# DISPC register map
Vendor: Texas Instruments
Registers are 32-bit, access per field, reset 0x0 unless marked. A register's access mark holds for its fields unless they carry their own. Offsets are as the file gives them; [hi:lo] are bit positions; {n}, {i} and the like mark numbered series; 'fields as' and 'values as' point back to an identical list.

## DISPC (part 2 of 6)
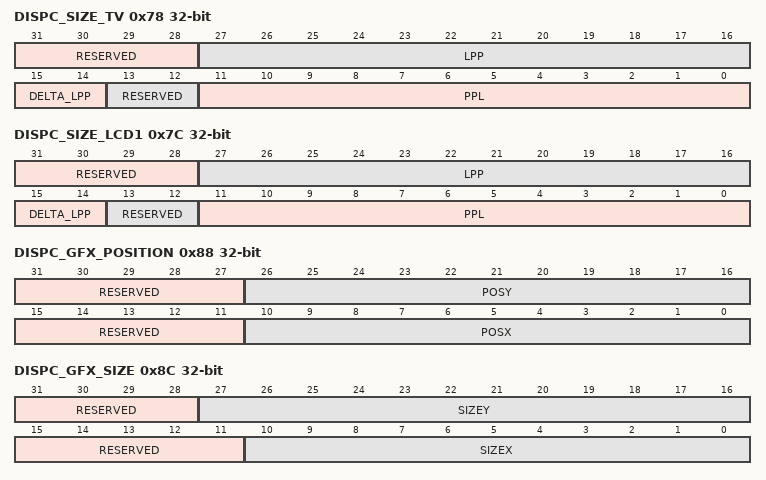
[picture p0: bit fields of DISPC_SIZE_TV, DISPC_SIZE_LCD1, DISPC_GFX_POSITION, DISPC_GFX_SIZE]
0x78 DISPC_SIZE_TV — The register configures the size of the TV output field (interlace), frame (progressive) (horizontal and vertical). Shadow register, updated on EVSYNC. A delta value is used to indicate if the odd field has same vertical size as the even field or +/- one line.
  [31:28] RESERVED ro — Write 0s for future compatibility. Reads return 0.
  [27:16] LPP rw — Lines per panel encoded value (from 1 to 4096) to specify the number of lines per panel.
  [15:14] DELTA_LPP rw — Indicates the delta size value of the odd field compared to the even field
    0=Same size; 1=PlusOne (Odd size = Even size +1); 2=MinusOne (Odd size = Even Size –1)
  [13:12] RESERVED ro — Write 0s for future compatibility. Reads return 0.
  [11:0] PPL rw — Pixels per line encoded value (from 1 to 4096) to specify the number of pixels contains within each line on the display.
0x7C DISPC_SIZE_LCD1 — The register configures the panel size (horizontal and vertical). Shadow register, updated on VFP start period of primary LCD. A delta value is used to indicate if the odd field has same vertical size as the even field or +/- one line.
  [31:28] RESERVED ro — Write 0s for future compatibility. Reads return 0.
  [27:16] LPP rw — Lines per panel encoded value (from 1 to 4096) to specify the number of lines per panel (program to value minus 1).
  [15:14] DELTA_LPP rw — Indicates the delta size value of the odd field compared to the even field
    0=Same size; 1=PlusOne (Odd size = Even size +1); 2=MinusOne (Odd size = Even Size -1)
  [13:12] RESERVED ro — Write 0s for future compatibility. Reads return 0.
  [11:0] PPL rw — Pixels per line encoded value (from 1 to 4096) to specify the number of pixels contains within each line on the display (program to value minus 1). In STALL mode, any value is valid. In non STALL mode, only values multiple of 8 pixels are valid.
0x80 DISPC_GFX_BA_j_0 rw — The register configures the base address of the graphics buffer displayed in the graphics window (0 and 1 :for ping-pong mechanism with external trigger, based on the field polarity, 0 only used when graphics pipeline on the LCD output and 0 and 1 when on the TV output). Shadow register, updated on VFP start period of primary LCD or VFP start period of the secondary LCD or VFP start period of the third LCD or EVSYNC or when.GOWB is set to 1 by software and current WB frame is finished (no more data in the write-back pipeline). The synchronization event is defined based on the output using the pipeline: primary LCD, secondary LCD, third LCD, TV output or write-back to the memory
  [31:0] BA — Graphics base address Base address of the graphics buffer (aligned on pixel size boundary) (in case 1-, 2-, and 4-bpp, byte alignment is required, in case of RGB24 packed format, 4-pixel alignment is required) When the TILER is addressed, the bits: [28:27] = 0x0 for 8-bit tiled [28:27] = 0x1 for 16-bit tiled [28:27] = 0x2 for 32-bit tiled [28:27] = 0x3 for page mode [31:29] = 0x0 for 0-degree view [31:29] = 0x1 for 180-degree view + mirroring [31:29] = 0x2 for 0-degree view + mirroring [31:29] = 0x3 for 180-degree view [31:29] = 0x4 for 270-degree view + mirroring [31:29] = 0x5 for 270-degree view [31:29] = 0x6 for 90-degree view [31:29] = 0x7 for 90-degree view + mirroring Otherwise the bits indicated the corresponding bit address to access the SDRAM.
0x84 DISPC_GFX_BA_j_1 rw — The register configures the base address of the graphics buffer displayed in the graphics window (0 and 1 :for ping-pong mechanism with external trigger, based on the field polarity, 0 only used when graphics pipeline on the LCD output and 0 and 1 when on the TV output). Shadow register, updated on VFP start period of primary LCD or VFP start period of the secondary LCD or VFP start period of the third LCD or EVSYNC or when.GOWB is set to 1 by software and current WB frame is finished (no more data in the write-back pipeline). The synchronization event is defined based on the output using the pipeline: primary LCD, secondary LCD, third LCD, TV output or write-back to the memory
  fields as DISPC_GFX_BA_j_0
0x88 DISPC_GFX_POSITION — The register configures the position of the graphics window. Shadow register, updated on VFP start period of primary LCD or VFP start period of the secondary LCD or VFP start period of the third LCD or EVSYNC or when.GOWB is set to 1 by software and current WB frame is finished (no more data in the write-back pipeline). The synchronization event is defined based on the output using the pipeline: primary LCD, secondary LCD, third LCD, TV output or write-back to the memory
  [31:27] RESERVED ro — Write 0s for future compatibility. Reads return 0.
  [26:16] POSY rw — Y position of the graphics window. Encoded value (from 0 to 2047) to specify the Y position of the graphics window on the screen. The line at the top has the Y-position 0.
  [15:11] RESERVED ro — Write 0s for future compatibility. Reads return 0.
  [10:0] POSX rw — X position of the graphics window. Encoded value (from 0 to 2047) to specify the X position of the graphics window on the screen. The first pixel on the left of the screen has the X-position 0.
0x8C DISPC_GFX_SIZE — The register configures the size of the graphics window. Shadow register, updated on VFP start period of primary LCD or VFP start period of the secondary LCD or VFP start period of the third LCD or EVSYNC or when.GOWB is set to 1 by software and current WB frame is finished (no more data in the write-back pipeline). The synchronization event is defined based on the output using the pipeline: primary LCD, secondary LCD, third LCD, TV output or write-back to the memory
  [31:28] RESERVED ro — Write 0s for future compatibility. Reads return 0.
  [27:16] SIZEY rw — Number of lines of the graphics window. Encoded value (from 1 to 4096) to specify the number of lines of the graphics window (program to value minus 1).
  [15:11] RESERVED ro — Write 0s for future compatibility. Reads return 0.
  [10:0] SIZEX rw — Number of pixels of the graphics window. Encoded value (from 1 to 2048) to specify the number of pixels per line of the graphics window (program to value minus 1).
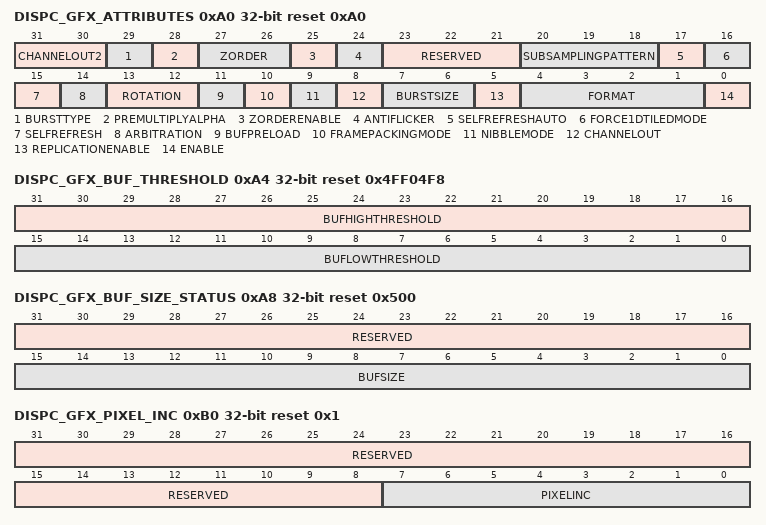
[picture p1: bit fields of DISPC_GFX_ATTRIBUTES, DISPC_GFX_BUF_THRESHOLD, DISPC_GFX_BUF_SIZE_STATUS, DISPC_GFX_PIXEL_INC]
0xA0 DISPC_GFX_ATTRIBUTES reset 0xA0 — The register configures the graphics attributes. Shadow register, updated on VFP start period of primary LCD or VFP start period of the secondary LCD or VFP start period of the third LCD or EVSYNC or when.GOWB is set to 1 by software and current WB frame is finished (no more data in the write-back pipeline). The synchronization event is defined based on the output using the pipeline: primary LCD, secondary LCD, third LCD, TV output or write-back to the memory
  [31:30] CHANNELOUT2 rw — It is not used if CHANNELOUT is set to TV. Reserved when CHANNELOUT = 1 (should set to zero) wr: immediate
    0=Primary_LCD_output_selected; 1=Secondary_LCD_output_selected; 2=Third_LCD_output_selected; 3=Write-back output to the memory selected
  [29] BURSTTYPE rw — The type of burst can be INCR (incremental) or BLCK (2D block). The 2D block is required when the TILER is targeted by the DMA engine. (It does not apply to the palette loading OCP requests using INCR burst only)
    0=INC (INC burst type is used.); 1=2D_block_burst_type_is_used
  [28] PREMULTIPLYALPHA rw — The field configures the DISPC GFX to process incoming data as premultiplied alpha data or non premultiplied alpha data. Default setting is non premultiplied alpha data.
    0=PremultipliedAlpha (Non premultiplyalpha data color component); 1=PremultipliedAlpha (Premultiplyalpha data color component)
  [27:26] ZORDER rw — Z-Order defining the priority of the layer compared to others when overlaying. It is software responsibility to ensure that each layer connected to the same overlay manager has a different z-order value. If bit 25 is set to 0, the ZORDER bit field is ignored and replaced by the value 0.
    0=Z-order 0: layer above solid background color and below layer with higher Z-order values; 1=Z-order 1: layer above layer with z-order value of 0 and below layers with z-order values of 2 and 3; 3=Z-order 3: layer above all the other layers; 2=Z-order 2: layer above layers with z-order value of 0 and 1 and below layer with z-order value of 3
  [25] ZORDERENABLE rw — Z-order Enable. The bit field ZORDER is only used when the Z-order is enabled.
    0=Z-order disabled. The Z-order of the layer is 0.; 1=ZorderEnb (Z-order enabled. The Z-order is defined by the bit field ZORDER (bits 26 and 27).)
  [24] ANTIFLICKER rw — Antiflicker filtering using a 3-tap filter with hardcoded coefficients (1/4, 1/2, 1/4)
    0=AFDis (Antiflicker disabled.); 1=AFEnb (Antiflicker enabled.)
  [23:21] RESERVED ro — Write 0s for future compatibility. Reads return 0.
  [20:18] SUBSAMPLINGPATTERN rw — Subsampling pattern setting.
  [17] SELFREFRESHAUTO rw — Automatic self-refresh mode
    0=SelfRefreshAutoDis (The transition from Selfrefresh disabled to enabled is controlled by software); 1=SelfRefreshAutoEn (The transition from Selfrefresh disabled to enabled is controlled only by hardware)
  [16] FORCE1DTILEDMODE rw — Force TILED regions access to 1D or 2D.
    0=TiledRegions2DAccess (2D accesses for tiled regions); 1=TiledRegions1DAccess (1D accesses for tiled regions)
  [15] SELFREFRESH rw — Enables the self refresh of the graphics window from its own DMA buffer. This bit should be set only after having set the GO bit of the channel and read back a zero in its field.
    0=SelfRefreshDis (The graphics pipeline accesses the interconnect to fetch data from the system memory.); 1=SelfRefreshEnb (The graphics pipeline does not need anymore to fetch data from memory. Only the graphics DMA buffer is used. It takes effect after the frame has been loaded in the DMA buffer.)
  [14] ARBITRATION rw — Determines the priority of the graphics pipeline. When the graphics pipeline is one of the high priority pipelines. The arbitration wheel gives always the priority first to the high priority pipelines using round-robin between them. When there is only normal priority pipelines sending requests, the round-robin applies between them.
    0=NormalPrio (The graphics pipeline is one of the normal priority pipeline.); 1=HighPrio (The graphics pipeline is one of the high priority pipeline.)
  [13:12] ROTATION rw — Graphics rotation flag
    0=No rotation; 1=Rot90 (Rotation by 90 degrees); 3=Rot270 (Rotation by 270 degrees); 2=Rot180 (Rotation by 180 degrees)
  [11] BUFPRELOAD rw — Graphics preload value
    0=DefVal (Hardware prefetches pixels up to the preload value defined in the preload register); 1=HighThres (Hardware prefetches pixels up to high threshold value)
  [10] FRAMEPACKINGMODE rw — Frame packing mode control.
    0=FPMDis (Frame Packing mode is disabled); 1=FPMEnb (Frame Packing mode is enabled)
  [9] NIBBLEMODE rw — Graphics nibble mode (only for 1-, 2- and 4 bpp)NOTE: BITMAP formats and associated Nibble Mode are not supported in this family of devices. .
    0=NibMDis (Nibble mode is disabled); 1=NibMEnb (Nibble mode is enabled)
  [8] CHANNELOUT rw — Graphics Channel Out configuration: LCD, WB or TV. wr: immediate
    0=LCDOpSel (LCD output or WB to the memory selected. bit fields 31 and 30 defines the output associated (primary, secondary or write-back).); 1=TVOpSel (TV output selected)
  [7:6] BURSTSIZE rw — Graphics DMA burst size
    0=Burst2x128 (2 × 128-bit bursts); 1=Burst4x128 (4 × 128-bit bursts); 2=Burst8x128 (8 × 128-bit bursts)
  [5] REPLICATIONENABLE rw — Graphics replication enabled: RGB . ARGB, and RGBA formats are converted into ARGB32-8888 using replication of the MSBs or 0s
    0=GRLogEnb (Disable graphics replication logic. The conversion to ARGB32-8888 is done by adding 0s for the LSBs); 1=GRLogDis (Enable graphics replication logic. The conversion to ARGB32-8888 is done by duplicating the MSBs for the LSBs)
  [4:1] FORMAT rw — Graphics format. It defines the pixel format when fetching the graphics picture into memory.
    6=RGB16 (RGB16-565); 10=RGBx12-4444; 7=ARGB16_1 (ARGB16-1555); 13=RGBA32 (RGBA32-8888); 8=xRGB24-8888 (32-bit container); 9=RGB24p (RGB24-888 (24-bit container)); 11=RGBA12 (RGBA12-4444); 4=xRGB12-4444; 5=ARGB16 (ARGB16-4444); 15=xRGB15-1555; 12=ARGB32 (ARGB32-8888); 3=BGRA32 (BGRA32-8888); 14=BitMap8 (RGBx24-8888 (24-bit RGB aligned on MSB of the 32-bit container))
  [0] ENABLE rw — Graphics enable
    0=Graphics disabled (graphics pipeline inactive and graphics window not present); 1=GraphicsEnb (Graphics enabled (graphics pipeline active and graphics window present on the screen))
0xA4 DISPC_GFX_BUF_THRESHOLD rw reset 0x4FF04F8 — The register configures the graphics buffer. Shadow register, updated on VFP start period of primary LCD or VFP start period of the secondary LCD or VFP start period of the third LCD or EVSYNC or when.GOWB is set to 1 by software and current WB frame is finished (no more data in the write-back pipeline). The synchronization event is defined based on the output using the pipeline: primary LCD, secondary LCD, third LCD, TV output or write-back to the memory
  [31:16] BUFHIGHTHRESHOLD — DMA buffer high threshold number of 128 bits defining the threshold value
  [15:0] BUFLOWTHRESHOLD — DMA buffer low threshold number of 128 bits defining the threshold value. The value put in this register must always be greater than zero.
0xA8 DISPC_GFX_BUF_SIZE_STATUS ro reset 0x500 — The register defines the Graphics buffer size
  [31:16] RESERVED — Write 0s for future compatibility. Reads return 0.
  [15:0] BUFSIZE — DMA buffer size in number of 128 bits
0xAC DISPC_GFX_ROW_INC rw reset 0x1 — The register configures the number of bytes to increment at the end of the row. Shadow register, updated on VFP start period of primary LCD or VFP start period of the secondary LCD or VFP start period of the third LCD or EVSYNC or when.GOWB is set to 1 by software and current WB frame is finished (no more data in the write-back pipeline). The synchronization event is defined based on the output using the pipeline: primary LCD, secondary LCD, third LCD, TV output or write-back to the memory
  [31:0] ROWINC — Number of bytes to increment at the end of the row Encoded unsigned value to specify the number of bytes to increment at the end of the row in the graphics buffer. The value 0 is invalid. The value 1 means next pixel. The value 1+n*bpp means increment of n pixels. The value 1- (n+1)*bpp means decrement of n pixels.
0xB0 DISPC_GFX_PIXEL_INC reset 0x1 — The register configures the number of bytes to increment between two pixels. For more information, see, Predecimation. Shadow register, updated on VFP start period of primary LCD or VFP start period of the secondary LCD or VFP start period of the third LCD or EVSYNC or when .GOWB is set to 1 by software and current WB frame is finished (no more data in the write-back pipeline). The synchronization event is defined based on the output using the pipeline: primary LCD, secondary LCD, third LCD, TV output or write-back to the memory
  [31:8] RESERVED ro — Write 0s for future compatibility. Reads return 0.
  [7:0] PIXELINC rw — Number of bytes to increment between two pixels. Encoded unsigned value (from 1 to 255) to specify the number of bytes between two pixels in the graphics buffer. The value 0 is invalid. The value 1 means next pixel. The value 1+n*bpp means increment of n pixels.
0xB8 DISPC_GFX_TABLE_BA rw — The register configures the base address of the palette buffer or the gamma table buffer. Shadow register, updated on VFP start period of primary LCD or VFP start period of the secondary LCD or VFP start period of the third LCD or EVSYNC or when.GOWB is set to 1 by software and current WB frame is finished (no more data in the write-back pipeline). The synchronization event is defined based on the output using the pipeline: primary LCD, secondary LCD, third LCD, TV output or write-back to the memory. NOTE: CLUT and BITMAP formats, and associated palette buffer, are not supported in this family of devices.
  [31:0] TABLEBA — Base address of the palette/gamma table buffer (24-bit entries in 32-bit containers, aligned on 32-bit boundary).NOTE: CLUT and BITMAP formats, and associated palette buffer, are not supported in this family of devices. .
0xBC DISPC_VID1_BA_j_0 rw — The register configures the base address of the video buffer for the video window 1 (DISPC_VID1_BA_0 and DISPC_VID1_BA_1 for ping-pong mechanism with external trigger, based on the field polarity otherwise only DISPC_VID1_BA_0 is used). Shadow register, updated on VFP start period of primary LCD or VFP start period of the secondary LCD or or VFP start period of the third LCD or EVSYNC or when.GOWB is set to 1 by software and current WB frame is finished (no more data in the write-back pipeline). The synchronization event is defined based on the output using the pipeline: primary LCD, secondary LCD, third LCD, TV output or write-back to the memory
  [31:0] BA — Video base address Base address of the video buffer (aligned on pixel size boundary except in case of RGB24 packed format, 4-pixel alignment is required; in case of YUV4:2:2, 2-pixel alignment is required, and YUV4:2:0, byte alignment is supported)). It case of YUV4:2:0 format, it indicates the base address of the Y buffer. When the TILER is addressed, the bits: [28:27] = 0x0 for 8-bit tiled [28:27] = 0x1 for 16-bit tiled [28:27] = 0x2 for 32-bit tiled [28:27] = 0x3 for page mode [31:29] = 0x0 for 0-degree view [31:29] = 0x1 for 180-degree view + mirroring [31:29] = 0x2 for 0-degree view + mirroring [31:29] = 0x3 for 180-degree view [31:29] = 0x4 for 270-degree view + mirroring [31:29] = 0x5 for 270-degree view [31:29] = 0x6 for 90-degree view [31:29] = 0x7 for 90-degree view + mirroring Otherwise the bits indicated the corresponding bit address to access the SDRAM.
0xC0 DISPC_VID1_BA_j_1 rw — The register configures the base address of the video buffer for the video window 1 (DISPC_VID1_BA_0 and DISPC_VID1_BA_1 for ping-pong mechanism with external trigger, based on the field polarity otherwise only DISPC_VID1_BA_0 is used). Shadow register, updated on VFP start period of primary LCD or VFP start period of the secondary LCD or or VFP start period of the third LCD or EVSYNC or when.GOWB is set to 1 by software and current WB frame is finished (no more data in the write-back pipeline). The synchronization event is defined based on the output using the pipeline: primary LCD, secondary LCD, third LCD, TV output or write-back to the memory
  fields as DISPC_VID1_BA_j_0
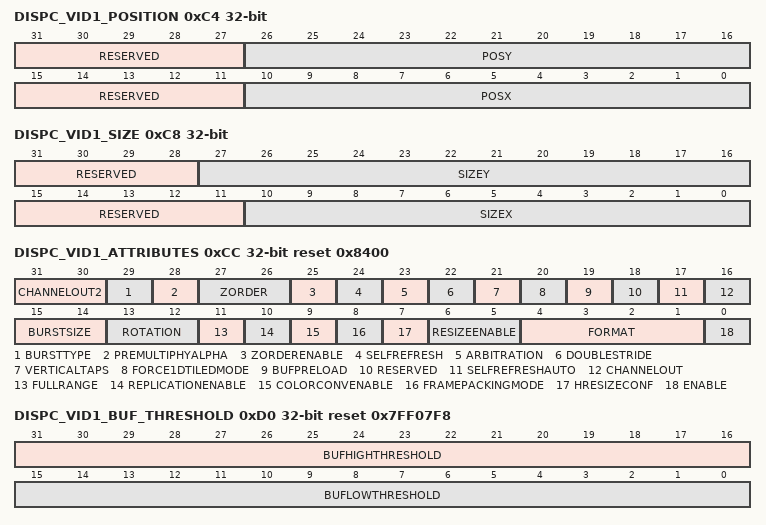
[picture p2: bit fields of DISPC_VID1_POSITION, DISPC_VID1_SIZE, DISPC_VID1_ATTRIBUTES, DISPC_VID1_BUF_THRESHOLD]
0xC4 DISPC_VID1_POSITION — The register configures the position of the video window 1. Shadow register, updated on VFP start period of primary LCD or VFP start period of the secondary LCD or VFP start period of the third LCD or EVSYNC or when.GOWB is set to 1 by software and current WB frame is finished (no more data in the write-back pipeline). The synchronization event is defined based on the output using the pipeline: primary LCD, secondary LCD, third LCD, TV output or write-back to the memory
  [31:27] RESERVED ro — Write 0s for future compatibility. Reads return 0.
  [26:16] POSY rw — Y position of the video window 1 Encoded value (from 0 to 2047) to specify the Y position of the video window 1 .The line at the top has the Y-position 0.
  [15:11] RESERVED ro — Write 0s for future compatibility. Reads return 0.
  [10:0] POSX rw — X position of the video window 1 Encoded value (from 0 to 2047) to specify the X position of the video window 1. The first pixel on the left of the display screen has the X-position 0.
0xC8 DISPC_VID1_SIZE — The register configures the size of the video window 1. Shadow register, updated on VFP start period of primary LCD or VFP start period of the secondary LCD or VFP start period of the third LCD, orEVSYNC or when.GOWB is set to 1 by software and current WB frame is finished (no more data in the write-back pipeline). The synchronization event is defined based on the output using the pipeline: primary LCD, secondary LCD, third LCD, TV output or write-back to the memory
  [31:28] RESERVED ro — Write 0s for future compatibility. Reads return 0.
  [27:16] SIZEY rw — Number of lines of the video 1 Encoded value (from 1 to 4096) to specify the number of lines of the video window 1. Program to value minus 1.
  [15:11] RESERVED ro — Write 0s for future compatibility. Reads return 0.
  [10:0] SIZEX rw — Number of pixels of the video window 1 Encoded value (from 1 to 2048) to specify the number of pixels of the video window 1. Program to value minus 1.
0xCC DISPC_VID1_ATTRIBUTES reset 0x8400 — The register configures the attributes of the video window 1. Shadow register, updated on VFP start period of primary LCD or VFP start period of the secondary LCD or VFP start period of the third LCD or EVSYNC or when.GOWB is set to 1 by software and current WB frame is finished (no more data in the write-back pipeline). The synchronization event is defined based on the output using the pipeline: primary LCD, secondary LCD, third LCD, TV output or write-back to the memory
  [31:30] CHANNELOUT2 rw — It is not used if CHANNELOUT is set to TV. Reserved when CHANNELOUT = 1 (should be set to zero) wr: immediate
    0=PrimaryLCDSel (Primary LCD output selected.); 1=SecondaryLCDSel (Secondary LCD output selected.); 2=ThirdLCDSel (Third LCD output selected.); 3=WriteBacksel (Write-back output to the memory selected.)
  [29] BURSTTYPE rw — The type of burst can be INCR (incremental) or BLCK (2D block). The 2D block is required when the TILER is targeted by the DMA engine.
    0=INC (INC burst type is used.); 1=BLCK (2D block burst type is used.)
  [28] PREMULTIPHYALPHA rw — The field configures the DISPC VID1 to process incoming data as premultiplied alpha data or non premultiplied alpha data. Default setting is non premultiplied alpha data.
    values as DISPC_GFX_ATTRIBUTES.PREMULTIPLYALPHA
  [27:26] ZORDER rw — Z-Order defining the priority of the layer compared to others when overlaying. It is software responsibility to ensure that each layer connected to the same overlay manager has a different z-order value. If bit 25 is set to 0, the ZORDER bit field is ignored and replaced by the value 0.
    values as DISPC_GFX_ATTRIBUTES.ZORDER
  [25] ZORDERENABLE rw — Z-order Enable. The bit field ZORDER is only used when the Z-order is enabled.
    values as DISPC_GFX_ATTRIBUTES.ZORDERENABLE
  [24] SELFREFRESH rw — Enables the self refresh of the video window from its own DMA buffer only.
    0=SelfRefreshDis (The video pipeline accesses the interconnect to fetch data from the system memory.); 1=SelfRefreshEnb (The video pipeline does not need anymore to fetch data from memory. Only the DMA buffer associated with the video1 is used. It takes effect after the frame has been loaded in the DMA buffer.)
  [23] ARBITRATION rw — Determines the priority of the video pipeline. The video pipeline is one of the high priority pipeline. The arbitration gives always the priority first to the high priority pipelines using round-robin between them. When there is only normal priority pipelines sending requests, the round-robin applies between them.
    0=NormalPrio (The video pipeline is one of the normal priority pipeline.); 1=HighPrio (The video pipeline is one of the high priority pipeline.)
  [22] DOUBLESTRIDE rw — Determines if the stride for CbCr buffer is the 1x or 2x of the Y buffer stride. It is only used in case of YUV4:2:0.
    0=Initial (The CbCr stride value is equal to the Y stride.); 1=Double (The CbCr stride value is double to the Y stride.)
  [21] VERTICALTAPS rw — Video vertical resize tap number. The vertical polyphase filter can be configured in 3-tap or 5-tap configuration. According to the number of taps, the maximum input picture width is double while using 3-tap compared to 5-tap.
    0=taps3 (3 taps are used for the vertical filtering logic. The 2 other taps are not used. The associated bit fields for the 2 other taps coefficients do not need to be initialized.); 1=taps5 (5 taps are used for the vertical filtering logic.)
  [20] FORCE1DTILEDMODE rw — Force TILED regions access to 1D or 2D.
    values as DISPC_GFX_ATTRIBUTES.FORCE1DTILEDMODE
  [19] BUFPRELOAD rw — Video Preload Value
    values as DISPC_GFX_ATTRIBUTES.BUFPRELOAD
  [18] RESERVED ro — Write 0s for future compatibility. Reads return 0.
  [17] SELFREFRESHAUTO rw — Automatic self-refresh mode
    0=SelfRefreshAutoDis (The transition from SELFREFRESH disabled to enabled is controlled by SW.); 1=SelfRefreshAutoEn (The transition from SELFREFRESH disabled to enabled is controlled only by hardware.)
  [16] CHANNELOUT rw — Video channel out configuration: LCD, WB or TV. wr: immediate
    0=LCDOp (LCD output or WB to the memory selected. bit fields 31 and 30 defines the output associated (primary, secondary or write-back).); 1=TVOp (TV output selected)
  [15:14] BURSTSIZE rw — Video DMA burst size
    0=Burst2x128b (2x128bit bursts); 1=Burst4x128b (4x128bit bursts); 2=Burst8x128b (8x128bit bursts)
  [13:12] ROTATION rw — Video rotation flag
    values as DISPC_GFX_ATTRIBUTES.ROTATION
  [11] FULLRANGE rw — Color space conversion full range setting.
    0=Limrange (Limited range selected: 16 subtracted from Y before color space conversion); 1=Full range selected: Y is not modified before the color space conversion
  [10] REPLICATIONENABLE rw
    0=VRepLDis (Disable Video replication logic); 1=VRepLEnb (Enable Video replication logic)
  [9] COLORCONVENABLE rw — Enable the color space conversion. The hardware does not enable/disable the conversion based on the pixel format. The bit field shall be reset when the format is not YUV.
    0=ColSpCDis (Disable Color Space Conversion YUV to RGB); 1=ColSpCEnb (Enable Color Space Conversion YUV to RGB)
  [8] FRAMEPACKINGMODE rw — Frame packing mode control.
    values as DISPC_GFX_ATTRIBUTES.FRAMEPACKINGMODE
  [7] HRESIZECONF ro — Write 0s for future compatibility. Reads return 0.
  [6:5] RESIZEENABLE rw — Video Resize Enable
    0=ReSizeProc (Disable both horizontal and vertical resize processing); 1=HReSize (Enable the horizontal resize processing); 3=HVReSize (Enable both horizontal and vertical resize processing); 2=VReSize (Enable the vertical resize processing)
  [4:1] FORMAT rw — Video Format. It defines the pixel format when fetching the video 1 picture into memory.
    6=RGB16 (RGB16-565); 1=RGBx12 (RGB12x-4444); 10=YUV2 (YUV2 4:2:2 co-sited); 7=ARGB16_1 (ARGB16-1555); 13=RGBA32 (RGBA32-8888); 0=NV12 (NV12 4:2:0 2 buffers (Y + UV)); 2=RGBA12 (RGBA12-4444); 8=xRGB24-8888 (32-bit container); 9=RGB24p (RGB24-888 (24-bit container)); 11=UYVY (UYVY 4:2:2 co-sited); 5=ARGB16 (ARGB16-4444); 15=xRGB15-1555; 12=ARGB32 (ARGB32-8888); 4=xRGB12-4444; 3=BGRA32 (BGRA32-8888); 14=xRGB12 (RGBx24-8888 (24-bit RGB aligned on MSB of the 32-bit container))
  [0] ENABLE rw — Video Enable
    0=Video disabled (video pipeline inactive and window not present); 1=VideoEnb (Video enabled (video pipeline active and window present on the screen))
0xD0 DISPC_VID1_BUF_THRESHOLD rw reset 0x7FF07F8 — The register configures the video buffer associated with the video pipeline 1. Shadow register, updated on VFP start period of primary LCD or VFP start period of the secondary LCD or VFP start period of the third LCD or EVSYNC or when.GOWB is set to 1 by software and current WB frame is finished (no more data in the write-back pipeline). The synchronization event is defined based on the output using the pipeline: primary LCD, secondary LCD, third LCD, TV output or write-back to the memory
  [31:16] BUFHIGHTHRESHOLD — Video DMA buffer high threshold number of 128 bits defining the threshold value
  [15:0] BUFLOWTHRESHOLD — DMA buffer low threshold number of 128 bits defining the threshold value
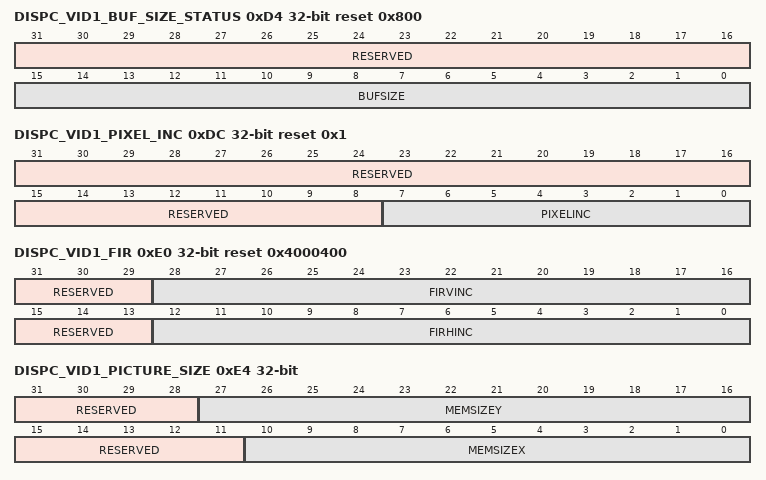
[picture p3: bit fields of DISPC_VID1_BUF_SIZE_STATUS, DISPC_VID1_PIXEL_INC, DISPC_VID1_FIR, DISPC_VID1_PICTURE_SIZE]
0xD4 DISPC_VID1_BUF_SIZE_STATUS ro reset 0x800 — The register defines the Video buffer size for the video pipeline 1.
  [31:16] RESERVED — Write 0s for future compatibility. Reads return 0.
  [15:0] BUFSIZE — Video 1 DMA buffer size in number of 128-bits
0xD8 DISPC_VID1_ROW_INC rw reset 0x1 — The register configures the number of bytes to increment at the end of the row for the buffer associated with the video window 1. Shadow register, updated on VFP start period of primary LCD or VFP start period of the secondary LCD or VFP start period of the third LCD or EVSYNC or when.GOWB is set to 1 by software and current WB frame is finished (no more data in the write-back pipeline). The synchronization event is defined based on the output using the pipeline: primary LCD, secondary LCD, third LCD, TV output or write-back to the memory
  [31:0] ROWINC — Number of bytes to increment at the end of the row Encoded signed value (from 21 to 2) to specify the number of bytes to increment at the end of the row in the video buffer. The value 0 is invalid. The value 1 means next pixel. The value 1 + n * bpp means increment of n pixels. The value 1 (n + 1)* bpp means decrement of n pixels.
0xDC DISPC_VID1_PIXEL_INC reset 0x1 — The register configures the number of bytes to increment between two pixels for the buffer associated with the video window 2. For more information, see, Predecimation.The register is used only when the TILER is not present in the system in order to perform low performance rotation. When the TILER IP is present it is highly recommended to use it for performing the rotation. Shadow register, updated on VFP start period of primary LCD or VFP start period of the secondary LCD or VFP start period of the third LCD orEVSYNC or when .GOWB is set to 1 by software and current WB frame is finished (no more data in the write-back pipeline). The synchronization event is defined based on the output using the pipeline: primary LCD, secondary LCD, third LCD, TV output or write-back to the memory
  [31:8] RESERVED ro — Write 0s for future compatibility. Reads return 0.
  [7:0] PIXELINC rw — Number of bytes to increment between two pixels. Encoded unsigned value (from 1 to 255) to specify the number of bytes between two pixels in the video buffer. The value 0 is invalid. The value 1 means next pixel. The value 1 + n * bpp means increment of n pixels. For YUV4:2:0, maximum supported value is 128.
0xE0 DISPC_VID1_FIR reset 0x4000400 — The register configures the resize factors for horizontal and vertical up/downsampling of the video window 1. It is used for ARGB and Y setting. Shadow register, updated on VFP start period of primary LCD or VFP start period of the secondary LCD or VFP start period of the third LCD or EVSYNC or when.GOWB is set to 1 by software and current WB frame is finished (no more data in the write-back pipeline). The synchronization event is defined based on the output using the pipeline: primary LCD, secondary LCD, third LCD, TV output or write-back to the memory
  [31:29] RESERVED ro — Write 0s for future compatibility. Reads return 0.
  [28:16] FIRVINC rw — Vertical increment of the up/downsampling filter. Encoded value (from 1 to 4096). The value 0 is invalid. The values greater than 4096 are invalid.
  [15:13] RESERVED ro — Write 0s for future compatibility. Reads return 0.
  [12:0] FIRHINC rw — Horizontal increment of the up/downsampling filter. Encoded value (from 1 to 4096). The value 0 is invalid. The values greater than 4096 are invalid.
0xE4 DISPC_VID1_PICTURE_SIZE — The register configures the size of the video picture associated with the video layer 1 before up/down-scaling. Shadow register, updated on VFP start period of primary LCD or VFP start period of the secondary LCD or VFP start period of the third LCD, EVSYNC or when.GOWB is set to 1 by software and current WB frame is finished (no more data in the write-back pipeline). The synchronization event is defined based on the output using the pipeline: primary LCD, secondary LCD, third LCD, TV output or write-back to the memory
  [31:28] RESERVED ro — Write 0s for future compatibility. Reads return 0.
  [27:16] MEMSIZEY rw — Number of lines of the video picture. Encoded value (from 1 to 4096) to specify the number of lines of the video picture in memory (program to value minus 1). When predecimation is set, the value represents the size of the image after predecimation but the max size of the unpredecimated image size in memory is still bounded to 2.
  [15:11] RESERVED ro — Write 0s for future compatibility. Reads return 0.
  [10:0] MEMSIZEX rw — Number of pixels of the video picture Encoded value (from 1 to 2048) to specify the number of pixels of the video picture in memory (program to value minus 1). The size is limited to the size of the line buffer of the vertical sampling block in case the video picture is processed by the vertical filtering unit. (program to value minus 1). When predecimation is set, the value represents the size of the image after predecimation but the max size of the unpredecimated image size in memory is still bounded to 2.
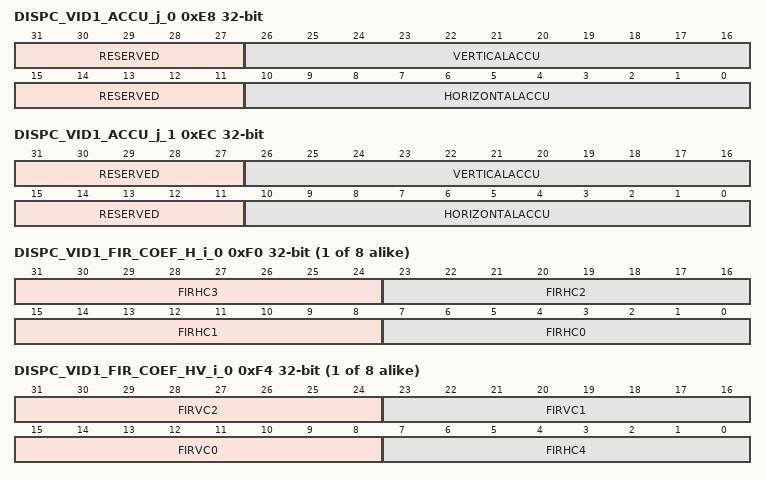
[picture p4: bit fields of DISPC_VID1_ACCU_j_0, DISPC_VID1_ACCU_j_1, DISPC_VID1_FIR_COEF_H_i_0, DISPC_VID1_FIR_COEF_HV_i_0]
0xE8 DISPC_VID1_ACCU_j_0 — The register configures the resize accumulator init values for horizontal and vertical up/downsampling of the video window 1 (DISPC_VID1_ACCU_0 and DISPC_VID1_ACCU_1 for ping-pong mechanism with external trigger, based on the field polarity) It is used for ARGB and Y setting. Shadow register, updated on VFP start period of primary LCD or VFP start period of the secondary LCD or VFP start period of the third LCD or EVSYNC or when.GOWB is set to 1 by software and current WB frame is finished (no more data in the write-back pipeline). The synchronization event is defined based on the output using the pipeline: primary LCD, secondary LCD, third LCD, TV output or write-back to the memory
  [31:27] RESERVED ro — Write 0s for future compatibility. Reads return 0.
  [26:16] VERTICALACCU rw — Vertical initialization accumulator value encoded value (from –1024 to 1023).
  [15:11] RESERVED ro — Write 0s for future compatibility. Reads return 0.
  [10:0] HORIZONTALACCU rw — Horizontal initialization accumulator value encoded value (from –1024 to 1023).
0xEC DISPC_VID1_ACCU_j_1 — The register configures the resize accumulator init values for horizontal and vertical up/downsampling of the video window 1 (DISPC_VID1_ACCU_0 and DISPC_VID1_ACCU_1 for ping-pong mechanism with external trigger, based on the field polarity) It is used for ARGB and Y setting. Shadow register, updated on VFP start period of primary LCD or VFP start period of the secondary LCD or VFP start period of the third LCD or EVSYNC or when.GOWB is set to 1 by software and current WB frame is finished (no more data in the write-back pipeline). The synchronization event is defined based on the output using the pipeline: primary LCD, secondary LCD, third LCD, TV output or write-back to the memory
  fields as DISPC_VID1_ACCU_j_0
{0xF0+8i} DISPC_VID1_FIR_COEF_H_i_{i} rw (i=0..7) — The bank of registers configure the up/down-scaling coefficients for the horizontal resize of the video picture associated with the video window 1 for the phases from 0 to 7. It is used for ARGB and Y setting. Shadow register, updated on VFP start period of primary LCD or VFP start period of the secondary LCD or VPF start pertiod of the third LCD, EVSYNC or when.GOWB is set to 1 by software and current WB frame is finished (no more data in the write-back pipeline). The synchronization event is defined based on the output using the pipeline: primary LCD, secondary LCD, third LCD, TV output or write-back to the memory
  [31:24] FIRHC3 — Signed coefficient C3 for the horizontal up/down-scaling with the phase n
  [23:16] FIRHC2 — Unsigned coefficient C2 for the horizontal up/down-scaling with the phase n
  [15:8] FIRHC1 — Signed coefficient C1 for the horizontal up/down-scaling with the phase n
  [7:0] FIRHC0 — Signed coefficient C0 for the horizontal up/down-scaling with the phase n
{0xF4+8i} DISPC_VID1_FIR_COEF_HV_i_{i} rw (i=0..7) — The bank of registers configure the down/up/down-scaling coefficients for the vertical and horizontal resize of the video picture associated with the video window 1 for the phases from 0 to 7. It is used for ARGB and Y setting. Shadow register, updated on VFP start period of primary LCD or VFP start period of the secondary LCD or VFP start period of the third LCD or EVSYNC or when.GOWB is set to 1 by software and current WB frame is finished (no more data in the write-back pipeline). The synchronization event is defined based on the output using the pipeline: primary LCD, secondary LCD, third LCD, TV output or write-back to the memory
  [31:24] FIRVC2 — Signed coefficient C2 for the vertical up/down-scaling with the phase n
  [23:16] FIRVC1 — Unsigned coefficient C1 for the vertical up/down-scaling with the phase n
  [15:8] FIRVC0 — Signed coefficient C0 for the vertical up/down-scaling with the phase n
  [7:0] FIRHC4 — Signed coefficient C4 for the horizontal up/down-scaling with the phase n
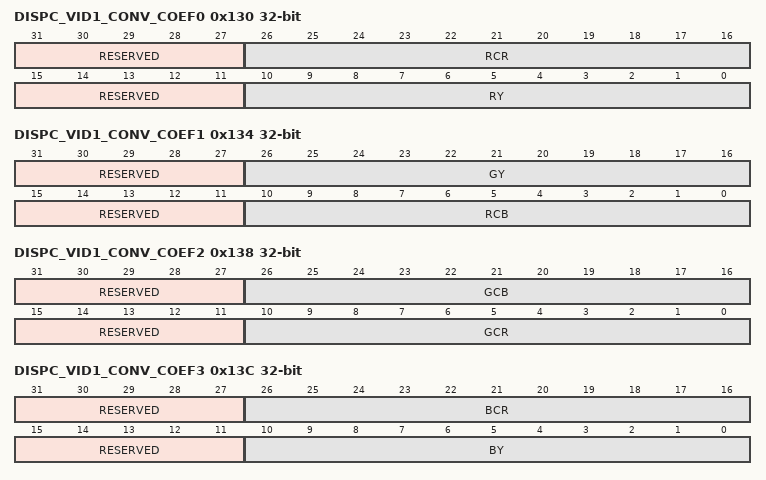
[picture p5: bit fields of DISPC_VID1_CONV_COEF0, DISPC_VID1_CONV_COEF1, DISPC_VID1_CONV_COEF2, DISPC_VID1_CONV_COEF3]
0x130 DISPC_VID1_CONV_COEF0 — The register configures the color space conversion matrix coefficients for the video pipeline 1. Shadow register, updated on VFP start period of primary LCD or VFP start period of the secondary LCD or VFP start period of the third LCD or EVSYNC or when.GOWB is set to 1 by software and current WB frame is finished (no more data in the write-back pipeline). The synchronization event is defined based on the output using the pipeline: primary LCD, secondary LCD, third LCD, TV output or write-back to the memory
  [31:27] RESERVED ro — Write 0s for future compatibility. Reads return 0.
  [26:16] RCR rw — RCr coefficient encoded signed value (from –1024 to 1023).
  [15:11] RESERVED ro — Write 0s for future compatibility. Reads return 0.
  [10:0] RY rw — RY coefficient encoded signed value (from –1024 to 1023).
0x134 DISPC_VID1_CONV_COEF1 — The register configures the color space conversion matrix coefficients for the video pipeline 1. Shadow register, updated on VFP start period of primary LCD or VFP start period of the secondary LCD or VFP start period of the third LCD or EVSYNC or when.GOWB is set to 1 by software and current WB frame is finished (no more data in the write-back pipeline). The synchronization event is defined based on the output using the pipeline: primary LCD, secondary LCD, third LCD, TV output or write-back to the memory
  [31:27] RESERVED ro — Write 0s for future compatibility. Reads return 0.
  [26:16] GY rw — GY coefficient encoded signed value (from -1024 to 1023).
  [15:11] RESERVED ro — Write 0s for future compatibility. Reads return 0.
  [10:0] RCB rw — RCb coefficient encoded signed value (from -1024 to 1023).
0x138 DISPC_VID1_CONV_COEF2 — The register configures the color space conversion matrix coefficients for the video pipeline 1. Shadow register, updated on VFP start period of primary LCD or VFP start period of the secondary LCD or VFP start period of the third LCD or EVSYNC or when.GOWB is set to 1 by software and current WB frame is finished (no more data in the write-back pipeline). The synchronization event is defined based on the output using the pipeline: primary LCD, secondary LCD, third LCD, TV output or write-back to the memory
  [31:27] RESERVED ro — Write 0s for future compatibility. Reads return 0.
  [26:16] GCB rw — GCb coefficient encoded signed value (from –1024 to 1023).
  [15:11] RESERVED ro — Write 0s for future compatibility. Reads return 0.
  [10:0] GCR rw — GCr coefficient encoded signed value (from –1024 to 1023).
0x13C DISPC_VID1_CONV_COEF3 — The register configures the color space conversion matrix coefficients for the video pipeline 1. Shadow register, updated on VFP start period of primary LCD or VFP start period of the secondary LCD or VFP start period of the third LCD or EVSYNC or when.GOWB is set to 1 by software and current WB frame is finished (no more data in the write-back pipeline). The synchronization event is defined based on the output using the pipeline: primary LCD, secondary LCD, third LCD, TV output or write-back to the memory
  [31:27] RESERVED ro — Write 0s for future compatibility. Reads return 0.
  [26:16] BCR rw — BCr coefficient encoded signed value (from –1024 to 1023).
  [15:11] RESERVED ro — Write 0s for future compatibility. Reads return 0.
  [10:0] BY rw — BY coefficient encoded signed value (from –1024 to 1023).
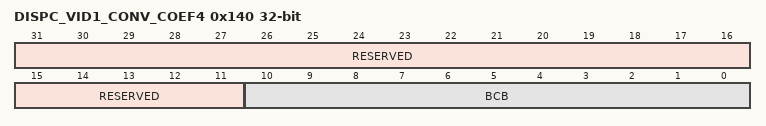
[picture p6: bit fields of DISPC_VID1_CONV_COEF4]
0x140 DISPC_VID1_CONV_COEF4 — The register configures the color space conversion matrix coefficients for the video pipeline 1. Shadow register, updated on VFP start period of primary LCD or VFP start period of the secondary LCD or VFP start period of the third LCD or EVSYNC or when.GOWB is set to 1 by software and current WB frame is finished (no more data in the write-back pipeline). The synchronization event is defined based on the output using the pipeline: primary LCD, secondary LCD, third LCD, TV output or write-back to the memory
  [31:11] RESERVED ro — Write 0s for future compatibility. Reads return 0.
  [10:0] BCB rw — BCb coefficient encoded signed value (from –1024 to 1023).
0x14C DISPC_VID2_BA_j_0 rw — The register configures the base address of the video buffer for the video window 2 (DISPC_VID2_BA_0 and DISPC_VID2_BA_1 for ping-pong mechanism with external trigger, based on the field polarity otherwise only DISPC_VID2_BA_0 is used)). Shadow register, updated on VFP start period of primary LCD or VFP start period of the secondary LCD or VFP start period of the third LCD or EVSYNC or when.GOWB is set to 1 by software and current WB frame is finished (no more data in the write-back pipeline). The synchronization event is defined based on the output using the pipeline: primary LCD, secondary LCD, third LCD, TV output or write-back to the memory
  [31:0] BA — Video base address Base address of the video buffer (aligned on pixel size boundary except in case of RGB24 packed format, 4-pixel alignment is required; in case of YUV4:2:2, 2-pixel alignment is required, and YUV4:2:0, byte alignment is supported)). In case of YUV4:2:0 format, it indicates the base address of the Y buffer. When the TILER is addressed, the bits: [28:27] = 0x0 for 8-bit tiled [28:27] = 0x1 for 16-bit tiled [28:27] = 0x2 for 32-bit tiled [28:27] = 0x3 for page mode [31:29] = 0x0 for 0-degree view [31:29] = 0x1 for 180-degree view + mirroring [31:29] = 0x2 for 0-degree view + mirroring [31:29] = 0x3 for 180-degree view [31:29] = 0x4 for 270-degree view + mirroring [31:29] = 0x5 for 270-degree view [31:29] = 0x6 for 90-degree view [31:29] = 0x7 for 90-degree view + mirroring Otherwise the bits indicated the corresponding bit address to access the SDRAM.
